AUTOSAR XML (schema 4-0-3)
package /App_IoHwAb
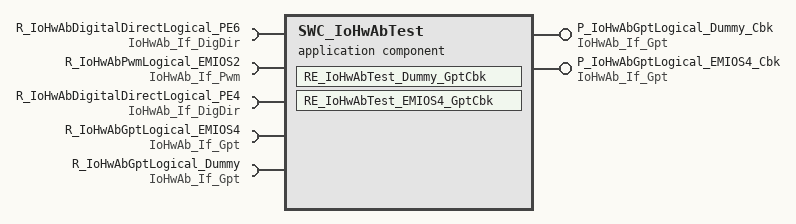
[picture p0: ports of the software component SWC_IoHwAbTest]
  application sw component type SWC_IoHwAbTest
    provide port P_IoHwAbGptLogical_Dummy_Cbk: server-com-spec{operation=Notification, queue-length=1}, provided-interface=IoHwAb_If_Gpt
    4 x require port:
      R_IoHwAbDigitalDirectLogical_PE6: required-com-specs=[IsInput, IsOutput, ReadDirect, SetToInput, SetToOutput, WriteDirect], required-interface=IoHwAb_If_DigDir
      R_IoHwAbPwmLogical_EMIOS2: required-com-specs=[SetDutyCycle, SetPeriodAndDuty, SetOutputToIdle, GetOutputState, DisableNotification, EnableNotification], required-interface=IoHwAb_If_Pwm
      R_IoHwAbDigitalDirectLogical_PE4: required-com-specs=[ReadDirect, WriteDirect, SetToInput, SetToOutput, IsInput, IsOutput], required-interface=IoHwAb_If_DigDir
      R_IoHwAbGptLogical_EMIOS4: required-com-specs=[StartTimer, StopTimer, GetTimeElapsed, GetTimeRemaining, DisableNotification, EnableNotification], required-interface=IoHwAb_If_Gpt
    provide port P_IoHwAbGptLogical_EMIOS4_Cbk: server-com-spec{operation=Notification, queue-length=1}, provided-interface=IoHwAb_If_Gpt
    require port R_IoHwAbGptLogical_Dummy: required-com-specs=[StartTimer, StopTimer, GetTimeElapsed, GetTimeRemaining, DisableNotification, EnableNotification], required-interface=IoHwAb_If_Gpt
    behavior SwcIB_IoHwAbTest
      timing event TE_IoHwAbTest: period=0.01
      operation invoked event OIE_RE_IoHwAbTest_EMIOS4_GptCbk_RE_IoHwAbTest_EMIOS4_GptCbk_Notification: start-on-event=RE_IoHwAbTest_EMIOS4_GptCbk, operation=P_IoHwAbGptLogical_EMIOS4_Cbk.Notification
      runnable RE_IoHwAbTest_Dummy_GptCbk
        sync call SSCP_RE_IoHwAbTest_Dummy_GptCbk_R_IoHwAbGptLogical_Dummy_Notification: operation=R_IoHwAbGptLogical_Dummy.Notification, timeout=0.0
      runnable RE_IoHwAbTest_EMIOS4_GptCbk
        sync call SSCP_RE_IoHwAbTest_EMIOS4_GptCbk_R_IoHwAbGptLogical_EMIOS4_Notification: operation=R_IoHwAbGptLogical_EMIOS4.Notification
